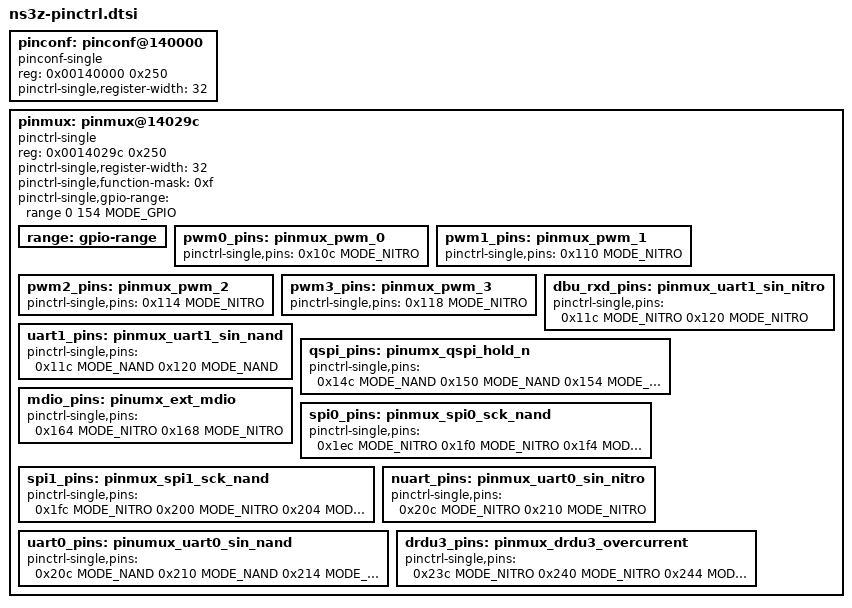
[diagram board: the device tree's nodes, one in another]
// SPDX-License-Identifier: (GPL-2.0 or BSD-3-Clause)
/*
 *  Copyright(c) 2019 Broadcom
 */

#include <dt-bindings/pinctrl/brcm,pinctrl-stingray.h>

pinconf: pinconf@140000 {
	compatible = "pinconf-single";
	reg = <0x00140000 0x250>;
	pinctrl-single,register-width = <32>;

	/* pinconf functions */
};

pinmux: pinmux@14029c {
	compatible = "pinctrl-single";
	reg = <0x0014029c 0x250>;
	#address-cells = <1>;
	#size-cells = <1>;
	pinctrl-single,register-width = <32>;
	pinctrl-single,function-mask = <0xf>;
	pinctrl-single,gpio-range = <
		&range 0 154 MODE_GPIO
		>;
	range: gpio-range {
		#pinctrl-single,gpio-range-cells = <3>;
	};

	pwm0_pins: pinmux_pwm_0 {
		pinctrl-single,pins = <
			0x10c MODE_NITRO
		>;
	};

	pwm1_pins: pinmux_pwm_1 {
		pinctrl-single,pins = <
			0x110 MODE_NITRO
		>;
	};

	pwm2_pins: pinmux_pwm_2 {
		pinctrl-single,pins = <
			0x114 MODE_NITRO
		>;
	};

	pwm3_pins: pinmux_pwm_3 {
		pinctrl-single,pins = <
			0x118 MODE_NITRO
		>;
	};

	dbu_rxd_pins: pinmux_uart1_sin_nitro {
		pinctrl-single,pins = <
			0x11c MODE_NITRO /* dbu_rxd */
			0x120 MODE_NITRO /* dbu_txd */
		>;
	};

	uart1_pins: pinmux_uart1_sin_nand {
		pinctrl-single,pins = <
			0x11c MODE_NAND /* uart1_sin */
			0x120 MODE_NAND /* uart1_out */
		>;
	};

	qspi_pins: pinumx_qspi_hold_n {
		pinctrl-single,pins = <
			0x14c MODE_NAND /* qspi_hold_n */
			0x150 MODE_NAND /* qspi_wp_n */
			0x154 MODE_NAND /* qspi_sck */
			0x158 MODE_NAND /* qspi_cs_n */
			0x15c MODE_NAND /* qspi_mosi */
			0x160 MODE_NAND /* qspi_miso */
		>;
	};

	mdio_pins: pinumx_ext_mdio {
		pinctrl-single,pins = <
			0x164 MODE_NITRO /* ext_mdio */
			0x168 MODE_NITRO /* ext_mdc */
		>;
	};

	spi0_pins: pinmux_spi0_sck_nand {
		pinctrl-single,pins = <
			0x1ec MODE_NITRO /* spi0_sck */
			0x1f0 MODE_NITRO /* spi0_rxd */
			0x1f4 MODE_NITRO /* spi0_fss */
			0x1f8 MODE_NITRO /* spi0_txd */
		>;
	};

	spi1_pins: pinmux_spi1_sck_nand {
		pinctrl-single,pins = <
			0x1fc MODE_NITRO /* spi1_sck */
			0x200 MODE_NITRO /* spi1_rxd */
			0x204 MODE_NITRO /* spi1_fss */
			0x208 MODE_NITRO /* spi1_txd */
		>;
	};

	nuart_pins: pinmux_uart0_sin_nitro {
		pinctrl-single,pins = <
			0x20c MODE_NITRO /* nuart_rxd */
			0x210 MODE_NITRO /* nuart_txd */
		>;
	};

	uart0_pins: pinumux_uart0_sin_nand {
		pinctrl-single,pins = <
			0x20c MODE_NAND /* uart0_sin */
			0x210 MODE_NAND /* uart0_out */
			0x214 MODE_NAND /* uart0_rts */
			0x218 MODE_NAND /* uart0_cts */
			0x21c MODE_NAND /* uart0_dtr */
			0x220 MODE_NAND /* uart0_dcd */
			0x224 MODE_NAND /* uart0_dsr */
			0x228 MODE_NAND /* uart0_ri */
		>;
	};

	drdu3_pins: pinmux_drdu3_overcurrent {
		pinctrl-single,pins = <
			0x23c MODE_NITRO /* drdu3_overcurrent */
			0x240 MODE_NITRO /* drdu3_vbus_ppc */
			0x244 MODE_NITRO /* drdu3_vbus_present */
			0x248 MODE_NITRO /* drdu3_id */
		>;
	};
};
